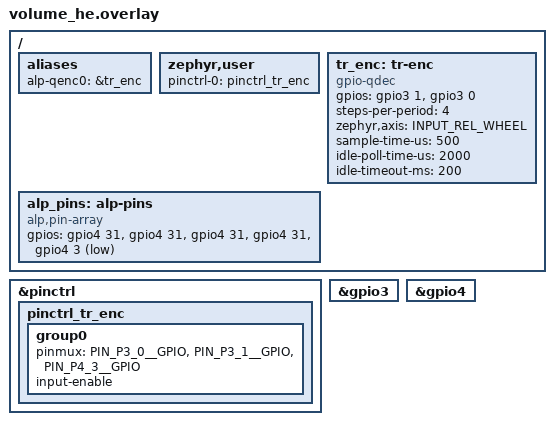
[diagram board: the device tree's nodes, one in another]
/*
 * volume_he.overlay -- TR_HP_SOUND builds, the HE's volume controls (CMakeLists.txt,
 * src/platform/volume_he.c): the EVK's rotary encoder and its push switch, mapped for the
 * portable API.
 *
 *   ENC0_X -> P3_0 = GPIO3 pin 0     ENC0_Y -> P3_1 = GPIO3 pin 1
 *   encoder push switch = E1M_GPIO_IO4 -> P4_3 = GPIO4 pin 3, active low, external 10k pull-up
 *   + 0.1 uF debounce (metadata/boards/e1m-evk.yaml, metadata/e1m_modules/aen/from-alif.tsv).
 * GPIO3 / GPIO4: not the GPIO5 port or the lpgpio island the HP's amps and CC3501E lines use.
 * Phase order: BENCH-CONFIRMED reversed with ENC0_X as phase A (a clockwise turn lowered the
 * volume), so tr_enc lists ENC0_Y (P3_1) first and ENC0_X (P3_0) second. That is also the order
 * aen-evk-demo's netlist note gives. tests/host/test_hp_combined.sh pins it.
 *
 * REN. A pad's input buffer is on only once pinctrl sets `input-enable`, and neither gpio_dw nor
 * gpio-qdec applies a pinctrl state (alp-sdk#2808 is the SDK gap). Until that is fixed in the
 * portable layer, the state sits on /zephyr,user and src/platform/volume_he.c applies it with
 * pinctrl_apply_state(): the sanctioned ad hoc pattern, as in
 * examples/aen/aen-camera-firstlight/trigger_gpio.overlay.
 */
#include <zephyr/dt-bindings/gpio/gpio.h>
#include <zephyr/dt-bindings/input/input-event-codes.h>
#include <zephyr/dt-bindings/pinctrl/alif-ensemble-pinctrl.h>

&pinctrl {
	pinctrl_tr_enc: pinctrl_tr_enc {
		group0 {
			pinmux = <PIN_P3_0__GPIO>, <PIN_P3_1__GPIO>, <PIN_P4_3__GPIO>;
			input-enable;
		};
	};
};

&gpio3 {
	status = "okay";
};

&gpio4 {
	status = "okay";
};

/ {
	aliases {
		alp-qenc0 = &tr_enc;
	};

	zephyr,user {
		pinctrl-0 = <&pinctrl_tr_enc>;
		pinctrl-names = "default";
	};

	/* Software quadrature decode (the SoC's UTIMER QEC block is an edge counter, not a decoder,
	 * #2037): one count per detent. idle-poll-time-us is required, gpio_dw has no both-edge
	 * interrupt (see examples/aen/aen-qenc-readout/boards/*.overlay). */
	tr_enc: tr-enc {
		compatible = "gpio-qdec";
		gpios = <&gpio3 1 GPIO_ACTIVE_HIGH>, <&gpio3 0 GPIO_ACTIVE_HIGH>;
		steps-per-period = <4>;
		zephyr,axis = <INPUT_REL_WHEEL>;
		sample-time-us = <500>;
		idle-poll-time-us = <2000>;
		idle-timeout-ms = <200>;
	};

	/* alp_gpio_open(pin_id) indexes this array by E1M pad number, so index 4 (IO4, the switch)
	 * needs entries 0..3 before it. The HE uses only IO4. IO0..IO3 name pin 31 of the 8-pin GPIO4
	 * controller: gpio_dw refuses it (-EINVAL) instead of driving a pad. They deliberately do NOT
	 * name the real IO0 (P9.1), IO2 (P12.5) or IO3 (P3.2) pads: P12_5 is CAM_MUX_SEL, hogged
	 * output-low by hp_vision, and a gpio_dw controller the HP owns (GPIO12) must not be
	 * instantiated on this core (cross-core INTEN / INTMASK / DDR writes and stray ISRs, the
	 * I2C2 / GPIO5 hazard class). GPIO3 (encoder) and GPIO4 (switch) are not touched by any
	 * hp_vision / sound overlay. */
	alp_pins: alp-pins {
		compatible = "alp,pin-array";
		gpios = <&gpio4 31 GPIO_ACTIVE_HIGH>, /* [0] IO0: not used here */
			<&gpio4 31 GPIO_ACTIVE_HIGH>, /* [1] IO1: not used here */
			<&gpio4 31 GPIO_ACTIVE_HIGH>, /* [2] IO2: not used here */
			<&gpio4 31 GPIO_ACTIVE_HIGH>, /* [3] IO3: not used here */
			<&gpio4 3 GPIO_ACTIVE_LOW>;   /* [4] IO4: P4.3, the encoder switch (external pull-up) */
	};
};
